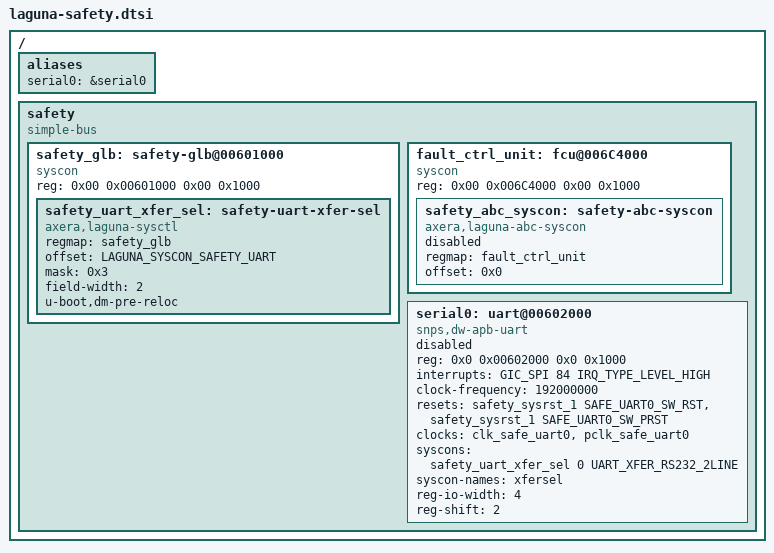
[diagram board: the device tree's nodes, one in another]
/* SPDX-License-Identifier: GPL-2.0+
 *
 * Laguna SoC Safety Domain device tree
 *
 * Copyright (C) 2024 Charleye <wangkart@aliyun.com>
 */

/ {
	aliases {
		serial0 = &serial0;
	};

	safety {
		compatible = "simple-bus";
		#address-cells = <2>;
		#size-cells = <2>;
		ranges;

		safety_glb: safety-glb@00601000 {
			compatible = "syscon", "simple-mfd";
			reg = <0x00 0x00601000 0x00 0x1000>;
			#address-cells = <1>;
			#size-cells = <1>;

			safety_uart_xfer_sel: safety-uart-xfer-sel {
				compatible = "axera,laguna-sysctl";
				#syscon-cells = <2>;
				regmap = <&safety_glb>;
				offset = <LAGUNA_SYSCON_SAFETY_UART>;
				mask = <0x3>;
				field-width = <2>;
				u-boot,dm-pre-reloc;
				u-boot,dm-spl;
			};
		};

		fault_ctrl_unit: fcu@006C4000 {
			compatible = "syscon", "simple-mfd";
			reg = <0x00 0x006C4000 0x00 0x1000>;
			#address-cells = <1>;
			#size-cells = <1>;

			safety_abc_syscon: safety-abc-syscon {
				compatible = "axera,laguna-abc-syscon";
				regmap = <&fault_ctrl_unit>;
				offset = <0x0>;
				status = "disabled";
			};
		};

		serial0: uart@00602000 {
			compatible = "snps,dw-apb-uart";
			reg = <0x0 0x00602000 0x0 0x1000>;
			interrupts = <GIC_SPI 84 IRQ_TYPE_LEVEL_HIGH>;
			clock-frequency = <192000000>; //192MHz
			resets = <&safety_sysrst_1 SAFE_UART0_SW_RST>,
			         <&safety_sysrst_1 SAFE_UART0_SW_PRST>;
			reset-names = "baudrst", "apb_prst";
			clocks = <&clk_safe_uart0>, <&pclk_safe_uart0>;
			clock-names = "baudclk", "apb_pclk";
			syscons = <&safety_uart_xfer_sel 0 UART_XFER_RS232_2LINE>;
			syscon-names = "xfersel";
			reg-io-width = <4>;
			reg-shift = <2>;
			status = "disabled";
		};
	};
};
